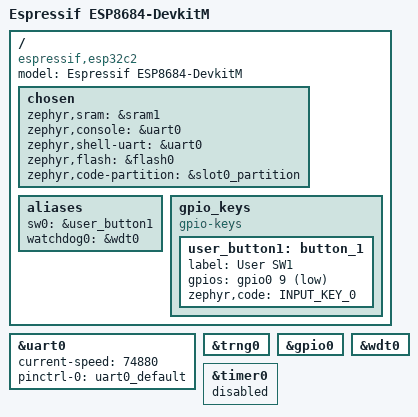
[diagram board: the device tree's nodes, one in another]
/*
 * Copyright (c) 2024 Espressif Systems (Shanghai) Co., Ltd.
 *
 * SPDX-License-Identifier: Apache-2.0
 */

/dts-v1/;

#include <espressif/esp32c2/esp8684_mini_h4.dtsi>
#include "esp8684_devkitm-pinctrl.dtsi"
#include <zephyr/dt-bindings/input/input-event-codes.h>
#include <espressif/partitions_0x0_default_2M.dtsi>

/ {
	model = "Espressif ESP8684-DevkitM";
	compatible = "espressif,esp32c2";

	chosen {
		zephyr,sram = &sram1;
		zephyr,console = &uart0;
		zephyr,shell-uart = &uart0;
		zephyr,flash = &flash0;
		zephyr,code-partition = &slot0_partition;
	};

	aliases {
		sw0 = &user_button1;
		watchdog0 = &wdt0;
	};

	gpio_keys {
		compatible = "gpio-keys";
		user_button1: button_1 {
			label = "User SW1";
			gpios = <&gpio0 9 (GPIO_PULL_UP | GPIO_ACTIVE_LOW)>;
			zephyr,code = <INPUT_KEY_0>;
		};
	};
};

&uart0 {
	status = "okay";
	current-speed = <74880>;
	pinctrl-0 = <&uart0_default>;
	pinctrl-names = "default";
};

&trng0 {
	status = "okay";
};

&gpio0 {
	status = "okay";
};

&wdt0 {
	status = "okay";
};

&timer0 {
	status = "disabled";
};
